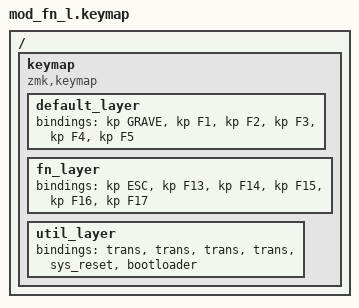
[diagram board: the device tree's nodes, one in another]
/*
 * copyright (c) 2025 ZMK project contributors
 *
 * SPDX-license-identifier: MIT
 */

#include <behaviors.dtsi>
#include <dt-bindings/zmk/keys.h>

/ {
    keymap {
        compatible = "zmk,keymap";

        default_layer {
            bindings = <
                &kp GRAVE   &kp F1  &kp F2  &kp F3  &kp F4  &kp F5
            >;
        };

        fn_layer {
            bindings = <
                &kp ESC &kp F13 &kp F14 &kp F15 &kp F16    &kp F17
            >;
        };

        util_layer {
            bindings = <
                &trans  &trans  &trans  &trans  &sys_reset &bootloader
            >;
        };
    };
};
